# DMTIMER register map
Vendor: Texas Instruments
Peripheral module from a debugger description file (folder am437x).
Registers are 32-bit, access per field, no defined reset value unless marked. A register's access mark holds for its fields unless they carry their own. Offsets are as the file gives them; lines under a group give offsets from that group; [hi:lo] are bit positions; {n}, {i} and the like mark numbered series; 'fields as' and 'values as' point back to an identical list; <NAME> marks a mode.

## DMTIMER
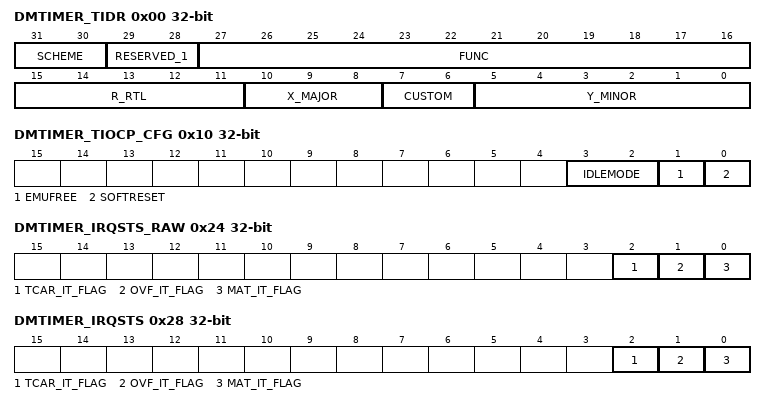
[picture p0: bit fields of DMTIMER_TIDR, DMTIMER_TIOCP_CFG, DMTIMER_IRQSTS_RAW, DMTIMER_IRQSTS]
0x00 DMTIMER_TIDR ro — This read only register contains the revision number of the module. A write to this register has no effect. This Register is used by software to track features, bugs, and compatibility.
  [31:30] SCHEME — Used to distinguish between old scheme and current
    1=en_2_0x1 (Highlander 0.8 scheme); 0=en_1_0x0 (Legacy ASP or WTBU scheme)
  [29:28] RESERVED_1 — Reads return 0
  [27:16] FUNC — Function indicates a software compatible module family. [[br]]If there is no level of software compatibility a new Func number (and hence REVISION) should be assigned.
  [15:11] R_RTL — RTL Version (R), maintained by IP design owner. [[br]]RTL follows a numbering such as X.Y.R.Z which are explained in this table. [[br]]R changes ONLY when: (1) PDS uploads occur which may have been due to spec changes (2) Bug fixes occur (3) Resets to '0' when X or Y changes. [[br]]Design team has an internal 'Z' (customer invisible) number which increments on every drop that happens due to DV and RTL updates. [[br]]Z resets to 0 when R increments.
  [10:8] X_MAJOR — Major Revision (X), maintained by IP specification owner. [[br]]X changes ONLY when: (1) There is a major feature addition. [[br]]An example would be adding Master Mode to Utopia Level2. [[br]]The Func field (or Class/Type in old PID format) will remain the same. [[br]]X does NOT change due to: (1) Bug fixes (2) Change in feature parameters.
  [7:6] CUSTOM — Indicates a special version for a particular device. [[br]]Consequence of use may avoid use of standard Chip Support Library (CSL) / Drivers.
  [5:0] Y_MINOR — Minor Revision (Y), maintained by IP specification owner. [[br]]Y changes ONLY when: (1) Features are scaled (up or down). [[br]]Flexibility exists in that this feature scalability may either be represented in the Y change or a specific register in the IP that indicates which features are exactly available. [[br]](2) When feature creeps from Is-Not list to Is list. [[br]]But this may not be the case once it sees silicon[[br]] in which case X will change. [[br]]Y does NOT change due to: (1) Bug fixes (2) Typos or clarifications (3) major functional/feature change/addition/deletion. [[br]]Instead these changes may be reflected via R, S, X as applicable. [[br]]Spec owner maintains a customer-invisible number 'S' which changes due to: (1) Typos/clarifications (2) Bug documentation. [[br]]Note that this bug is not due to a spec change but due to implementation. [[br]]Nevertheless, the spec tracks the IP bugs. [[br]]An RTL release (say for silicon PG1.1) that occurs due to bug fix should document the corresponding spec number (X.Y.S) in its release notes.
0x10 DMTIMER_TIOCP_CFG — This register controls the various parameters of the OCP interface
  [3:2] IDLEMODE rw — Power management, req/ack control
    3=en_4_0x3 (Smart-idle wakeup-capable mode: local target's idle state eventually follows (acknowledges) the system's idle requests, depending on the IP module's internal requirements. IP module may generate (IRQ- or DMA-request-related) wakeup events when in idle state. Mode is only relevant if the appropriate IP module "swakeup" output(s) is (are) implemented.); 2=en_3_0x2 (Smart-idle mode: local target's idle state eventually follows (acknowledges) the system's idle requests, depending on the IP module's internal requirements. IP module shall not generate (IRQ- or DMA-request-related) wakeup events.); 1=en_2_0x1 (No-idle mode: local target never enters idle state. Backup mode, for debug only.); 0=en_1_0x0 (Force-idle mode: local target's idle state follows (acknowledges) the system's idle requests unconditionally, i.e. regardless of the IP module's internal requirements. Backup mode, for debug only.)
  [1] EMUFREE rw — Sensitivity to emulation (debug) suspend event from Debug Subsystem.
    1=en_2_0x1 (The timer runs free. Debug suspend event is ignored.); 0=en_1_0x0 (The timer is frozen during a debug suspend event.)
  [0] SOFTRESET rw — Software reset.
    1=en_2_0x1 (Read 1 : initiate software reset Write 1 : Reset ongoing); 0=en_1_0x0 (Read 0 : reset done, no pending action Write 0 : no action)
0x20 DMTIMER_IRQ_EOI — This module supports DMA events with its interrupt signal. This register must be written to after the DMA completes in order for subsequent DMA events to be triggered from this module.
  [0] DMAEVENT_ACK rw — Write 0 to acknowledge DMA event has been completed. Module will be able to generate another DMA event only when the previous one has been acknowledged using this register. Reads always return 0.
0x24 DMTIMER_IRQSTS_RAW — Component interrupt request status. Check the corresponding secondary status register. Raw status is set even if event is not enabled. Write 1 to set the (raw) status, mostly for debug.
  [2] TCAR_IT_FLAG rw — IRQ status for Capture [[br]]Read 0 : No event pending [[br]]Write 0 : No action [[br]]Read 1 : IRQ event pending [[br]]Write 1 : Trigger IRQ event by software
  [1] OVF_IT_FLAG rw — IRQ status for Overflow [[br]]Read 0 : No event pending [[br]]Write 0 : No action [[br]]Read 1 : IRQ event pending [[br]]Write 1 : Trigger IRQ event by software
  [0] MAT_IT_FLAG rw — IRQ status for Match [[br]]Read 0 : No event pending [[br]]Write 0 : No action [[br]]Read 1 : IRQ event pending [[br]]Write 1 : Trigger IRQ event by software
0x28 DMTIMER_IRQSTS — Component interrupt request status. Check the corresponding secondary status register.Enabled status isn't set unless event is enabled.Write 1 to clear the status after interrupt has been serviced (raw status gets cleared, i.e. even if not enabled).
  [2] TCAR_IT_FLAG rw — IRQ status for Capture [[br]]Read 0 : No event pending [[br]]Write 0 : No action [[br]]Read 1 : IRQ event pending [[br]]Write 1 : Clear pending event, if any
  [1] OVF_IT_FLAG rw — IRQ status for Overflow [[br]]Read 0 : No event pending [[br]]Write 0 : No action [[br]]Read 1 : IRQ event pending [[br]]Write 1 : Clear pending event, if any
  [0] MAT_IT_FLAG rw — IRQ status for Match [[br]]Read 0 : No event pending [[br]]Write 0 : No action [[br]]Read 1 : IRQ event pending [[br]]Write 1 : Clear pending event, if any
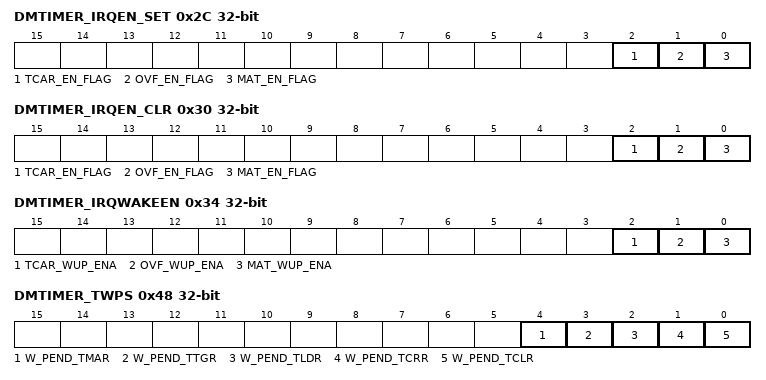
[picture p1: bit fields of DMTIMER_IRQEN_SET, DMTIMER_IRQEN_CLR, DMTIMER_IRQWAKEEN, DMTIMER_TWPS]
0x2C DMTIMER_IRQEN_SET — Component interrupt request enable Write 1 to set (enable interrupt). Readout equal to corresponding _CLR register.
  [2] TCAR_EN_FLAG rw — IRQ enable for Compare [[br]]Read 0 : IRQ event is disabled [[br]]Write 0 : No action [[br]]Read 1 : IRQ event is enabled [[br]]Write 1 : Set IRQ enable
  [1] OVF_EN_FLAG rw — IRQ enable for Overflow [[br]]Read 0 : IRQ event is disabled [[br]]Write 0 : No action [[br]]Read 1 : IRQ event is enabled [[br]]Write 1 : Set IRQ enable
  [0] MAT_EN_FLAG rw — IRQ enable for Match [[br]]Read 0 : IRQ event is disabled [[br]]Write 0 : No action [[br]]Read 1 : IRQ event is enabled [[br]]Write 1 : Set IRQ enable
0x30 DMTIMER_IRQEN_CLR — Component interrupt request enable Write 1 to clear (disable interrupt). Readout equal to corresponding _SET register.
  [2] TCAR_EN_FLAG rw — IRQ enable for Compare [[br]]Read 0 : IRQ event is disabled [[br]]Write 0 : No action [[br]]Read 1 : IRQ event is enabled [[br]]Write 1 : Clear IRQ enable
  [1] OVF_EN_FLAG rw — IRQ enable for Overflow [[br]]Read 0 : IRQ event is disabled [[br]]Write 0 : No action [[br]]Read 1 : IRQ event is enabled [[br]]Write 1 : Clear IRQ enable
  [0] MAT_EN_FLAG rw — IRQ enable for Match [[br]]Read 0 : IRQ event is disabled [[br]]Write 0 : No action [[br]]Read 1 : IRQ event is enabled [[br]]Write 1 : Clear IRQ enable
0x34 DMTIMER_IRQWAKEEN — Wakeup-enabled events taking place when module is idle shall generate an asynchronous wakeup.
  [all] fields
    1=en_2_0x1 (Wakeup enabled); 0=en_1_0x0 (Wakeup disabled)
  [2] TCAR_WUP_ENA rw — Wakeup generation for Compare
  [1] OVF_WUP_ENA rw — Wakeup generation for Overflow
  [0] MAT_WUP_ENA rw — Wakeup generation for Match
0x38 DMTIMER_TCLR — This register controls optional features specific to the timer functionality.
  [14] GPO_CFG rw — General Purpose Output - this register drives directly the PORGPOCFG output pin.
    1=en_2_0x1 (PORGPOCFG drives 1); 0=en_1_0x0 (PORGPOCFG drives 0)
  [14] IODIRECTION rw — Drives the direction for TriState buffers.
    1=en_2_0x1 (Tristate is input. Used for capture.); 0=en_1_0x0 (Tristates driven to output. Used for PWM output.)
  [13] CAPT_MODE rw — Capture mode select bit (first/second)
    1=en_2_0x1 (capture on second event); 0=en_1_0x0 (single capture)
  [12] PT rw — Pulse or toggle mode on PORTIMERPWM output pin
    1=en_2_0x1 (toggle); 0=en_1_0x0 (pulse)
  [11:10] TRG rw — Trigger output mode on PORTIMERPWM output pin
    3=en_4_0x3 (reserved); 2=en_3_0x2 (trigger on overflow and match); 1=en_2_0x1 (trigger on overflow); 0=en_1_0x0 (no trigger)
  [9:8] TCM rw — Transition Capture Mode on PIEVENTCAPT input pin (When the TCM field passed from (00) to any other combination then the TCAR_IT_FLAG and the edge detection logic are cleared)
    3=en_4_0x3 (Capture on booth edges of PIEVETCAPT); 2=en_3_0x2 (capture on both edge transition); 1=en_2_0x1 (capture on low to high transition); 0=en_1_0x0 (no capture)
  [7] SCPWM rw — This bit should be set or clear while the timer is stopped or the trigger is off.
    1=en_2_0x1 (set the PORTIMERPWM output pin and select negative pulse for pulse mode); 0=en_1_0x0 (clear the PORTIMERPWM output pin and select positive pulse for pulse mode)
  [6] CE rw — Compare enable
    1=en_2_0x1 (compare mode is enable); 0=en_1_0x0 (compare mode is disable)
  [5] PRE rw — Prescaler enable
    1=en_2_0x1 (The divided input pin clocks the counter); 0=en_1_0x0 (The TIMER clock input pin clocks the counter)
  [4:2] PTV rw — Pre-scale clock Timer Value
  [1] AR rw — Auto-reload mode
    1=en_2_0x1 (Auto-reload timer); 0=en_1_0x0 (One shot timer)
  [0] ST rw — Start/Stop timer control
    1=en_2_0x1 (Start timer); 0=en_1_0x0 (Stop timer. Only the counter is frozen In case of one-shot mode selected (AR =0), this bit is automatically reset by internal logic when the counter is overflowed.)
0x3C DMTIMER_TCRR rw — This register holds the value of the internal counter
  [31:0] TIMER_CTR — Value of TIMER counter
0x40 DMTIMER_TLDR rw — This register holds the timer's load value
  [31:0] LOAD_VALUE — Timer counter value loaded on overflow in auto-reload mode or on TTGR write access LOAD_VALUE must be different than the timer overflow value (0xFFFFFFFF).
0x44 DMTIMER_TTGR rw — The read value of this register is always 0xFFFF FFFF.
  [31:0] TTGR_VALUE — Writing in the TTGR register, TCRR will be loaded from TLDR and prescaler counter will be cleared Reload will be done regardless of the AR field value of TCLR register
0x48 DMTIMER_TWPS ro — This register contains the write posting bits for all writ-able functional registers
  [4] W_PEND_TMAR — When equal to 1, a write is pending to the TMAR register
  [3] W_PEND_TTGR — When equal to 1, a write is pending to the TTGR register
  [2] W_PEND_TLDR — When equal to 1, a write is pending to the TLDR register
  [1] W_PEND_TCRR — When equal to 1, a write is pending to the TCRR register
  [0] W_PEND_TCLR — When equal to 1, a write is pending to the TCLR register
0x4C DMTIMER_TMAR rw — The compare logic consists of a 32-bit wide, read/write data TMAR register and logic to compare counter
  [31:0] COMPARE_VALUE — Value to be compared to the timer counter
0x50 DMTIMER_TCAR1 ro
  [31:0] CAPTURE_VALUE1 — Timer counter value captured on an external event trigger
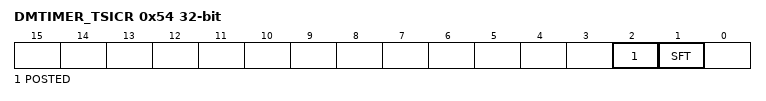
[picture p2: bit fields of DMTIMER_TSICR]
0x54 DMTIMER_TSICR — Timer Synchronous Interface Control Register
  [2] POSTED rw — Reset value of POSTED depends on hardware integration module at design time. [[br]]Software must read POSTED field to get the hardware module configuration.
    1=en_2_0x1 (posted mode active (clocks ratio needs to fit freq (timer) < freq (OCP)/4 frequency requirement)); 0=en_1_0x0 (posted mode inactive: will delay the command accept output signal.)
  [1] SFT rw — This bit reset all the functional part of the module
    1=en_2_0x1 (software reset is enabled); 0=en_1_0x0 (software reset is disabled)
0x58 DMTIMER_TCAR2 ro
  [31:0] CAPTURE_VALUE2 — Timer counter value captured on an external event trigger
